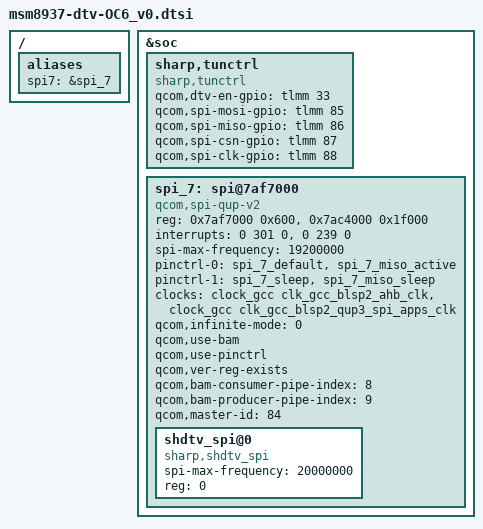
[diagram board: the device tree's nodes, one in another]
/*
 * Copyright (c) 2015-2016, The Linux Foundation. All rights reserved.
 *
 * This program is free software; you can redistribute it and/or modify
 * it under the terms of the GNU General Public License version 2 and
 * only version 2 as published by the Free Software Foundation.
 *
 * This program is distributed in the hope that it will be useful,
 * but WITHOUT ANY WARRANTY; without even the implied warranty of
 * MERCHANTABILITY or FITNESS FOR A PARTICULAR PURPOSE.  See the
 * GNU General Public License for more details.
 */

/ {

	aliases {
		spi7 = &spi_7;
	};

};

&soc {

	sharp,tunctrl {
		compatible = "sharp,tunctrl";
		qcom,dtv-en-gpio = <&tlmm  33 0x00>;
		qcom,spi-mosi-gpio = <&tlmm 85 0x00>;
		qcom,spi-miso-gpio = <&tlmm 86 0x00>;
		qcom,spi-csn-gpio = <&tlmm 87 0x00>;
		qcom,spi-clk-gpio = <&tlmm 88 0x00>;
	};

	spi_7: spi@7af7000 { /* BLSP2 QUP3 */
		compatible = "qcom,spi-qup-v2";
		#address-cells = <1>;
		#size-cells = <0>;
		reg-names = "spi_physical", "spi_bam_physical";
		reg = <0x7af7000 0x600>,
			<0x7ac4000 0x1f000>;
		interrupt-names = "spi_irq", "spi_bam_irq";
		interrupts = <0 301 0>, <0 239 0>;
		spi-max-frequency = <19200000>;
		pinctrl-names = "spi_default", "spi_sleep";
		pinctrl-0 = <&spi_7_default &spi_7_miso_active>;
		pinctrl-1 = <&spi_7_sleep &spi_7_miso_sleep>;
		clocks = <&clock_gcc clk_gcc_blsp2_ahb_clk>,
			<&clock_gcc clk_gcc_blsp2_qup3_spi_apps_clk>;
		clock-names = "iface_clk", "core_clk";
		qcom,infinite-mode = <0>;
		qcom,use-bam;
		qcom,use-pinctrl;
		qcom,ver-reg-exists;
		qcom,bam-consumer-pipe-index = <8>;
		qcom,bam-producer-pipe-index = <9>;
		qcom,master-id = <84>;
		status = "ok";
		shdtv_spi@0 {
			status = "ok";
			compatible = "sharp,shdtv_spi";
			spi-max-frequency = <20000000>;
			reg = <0>;
		};
	};

};
